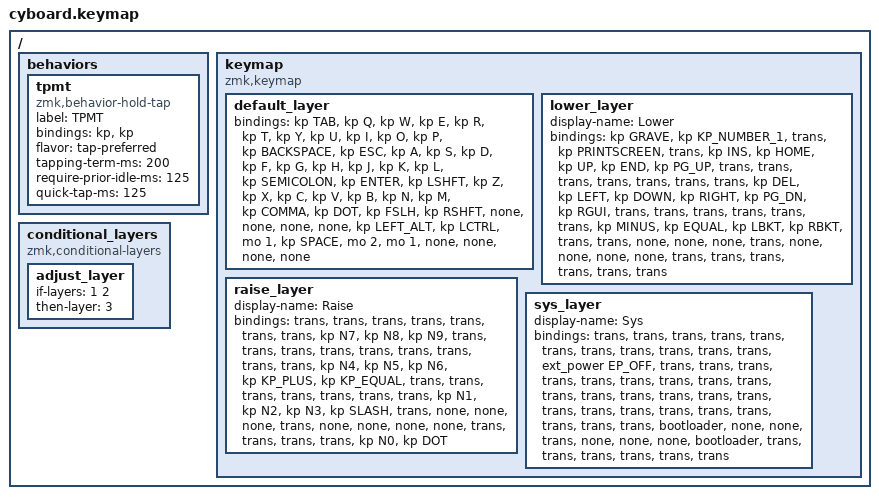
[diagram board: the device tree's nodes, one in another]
#include <behaviors.dtsi>
#include <dt-bindings/zmk/ext_power.h>
#include <dt-bindings/zmk/keys.h>

/ {
    behaviors {
        tpmt: tpmt {
            compatible = "zmk,behavior-hold-tap";
            label = "TPMT";
            bindings = <&kp>, <&kp>;

            #binding-cells = <2>;
            flavor = "tap-preferred";
            tapping-term-ms = <200>;
            require-prior-idle-ms = <125>;
            quick-tap-ms = <125>;
        };
    };

    keymap {
        compatible = "zmk,keymap";

        default_layer {
            bindings = <
&kp TAB  &kp Q  &kp W  &kp E  &kp R  &kp T  &kp Y  &kp U  &kp I  &kp O  &kp P  &kp BACKSPACE  &kp ESC  &kp A  &kp S  &kp D  &kp F  &kp G  &kp H  &kp J  &kp K  &kp L  &kp SEMICOLON  &kp ENTER  &kp LSHFT  &kp Z  &kp X  &kp C  &kp V  &kp B  &kp N  &kp M  &kp COMMA  &kp DOT  &kp FSLH  &kp RSHFT  &none  &none  &none  &none  &kp LEFT_ALT  &kp LCTRL  &mo 1  &kp SPACE  &mo 2  &mo 1  &none  &none  &none  &none
            >;
        };

        lower_layer {
            display-name = "Lower";
            bindings = <
&kp GRAVE  &kp KP_NUMBER_1  &trans  &kp PRINTSCREEN  &trans  &kp INS  &kp HOME  &kp UP  &kp END  &kp PG_UP  &trans  &trans  &trans  &trans  &trans  &trans  &trans  &kp DEL  &kp LEFT  &kp DOWN  &kp RIGHT  &kp PG_DN  &kp RGUI  &trans  &trans  &trans  &trans  &trans  &trans  &kp MINUS  &kp EQUAL  &kp LBKT  &kp RBKT  &trans  &trans  &none  &none  &none  &trans  &none  &none  &none  &none  &trans  &trans  &trans  &trans  &trans  &trans
            >;
        };

        raise_layer {
            display-name = "Raise";
            bindings = <
&trans  &trans  &trans  &trans  &trans  &trans  &trans  &kp N7  &kp N8  &kp N9  &trans  &trans  &trans  &trans  &trans  &trans  &trans  &trans  &trans  &kp N4  &kp N5  &kp N6  &kp KP_PLUS  &kp KP_EQUAL  &trans  &trans  &trans  &trans  &trans  &trans  &trans  &kp N1  &kp N2  &kp N3  &kp SLASH  &trans  &none  &none  &none  &trans  &none  &none  &none  &none  &trans  &trans  &trans  &trans  &kp N0  &kp DOT
            >;
        };

        sys_layer {
            display-name = "Sys";
            bindings = <
&trans  &trans  &trans  &trans  &trans  &trans  &trans  &trans  &trans  &trans  &trans  &ext_power EP_OFF  &trans  &trans  &trans  &trans  &trans  &trans  &trans  &trans  &trans  &trans  &trans  &trans  &trans  &trans  &trans  &trans  &trans  &trans  &trans  &trans  &trans  &trans  &trans  &trans  &bootloader  &none  &none  &trans  &none  &none  &none  &bootloader  &trans  &trans  &trans  &trans  &trans  &trans
            >;
        };
    };

    conditional_layers {
        compatible = "zmk,conditional-layers";

        adjust_layer {
            if-layers = <1 2>;
            then-layer = <3>;
        };
    };
};
